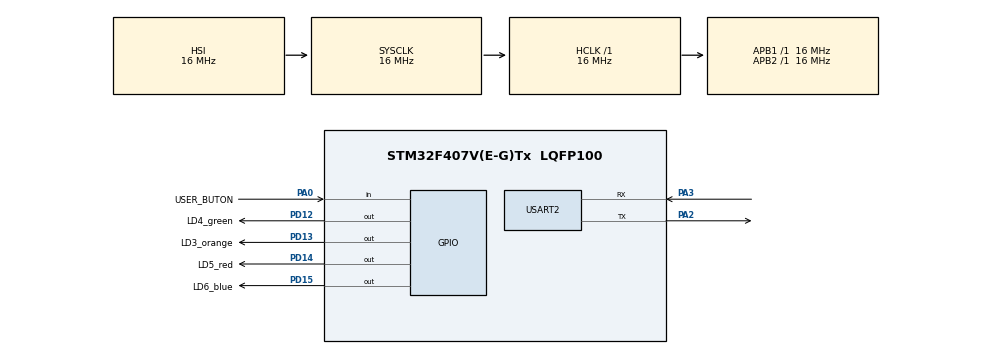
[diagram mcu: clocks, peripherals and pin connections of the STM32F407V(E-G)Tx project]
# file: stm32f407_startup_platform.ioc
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Mcu.Family=STM32F4
Mcu.Name=STM32F407V(E-G)Tx
Mcu.Package=LQFP100
NVIC.PriorityGroup=NVIC_PRIORITYGROUP_4
PA0-WKUP.GPIO_Label=USER_BUTON
PA0-WKUP.Signal=GPIO_Input
PA13.Mode=Serial_Wire
PA13.Signal=SYS_JTMS-SWDIO
PA14.Mode=Serial_Wire
PA14.Signal=SYS_JTCK-SWCLK
PA2.Mode=Asynchronous
PA2.Signal=USART2_TX
PA3.Mode=Asynchronous
PA3.Signal=USART2_RX
PD12.GPIO_Label=LD4_green
PD12.Signal=GPIO_Output
PD13.GPIO_Label=LD3_orange
PD13.Signal=GPIO_Output
PD14.GPIO_Label=LD5_red
PD14.Signal=GPIO_Output
PD15.GPIO_Label=LD6_blue
PD15.Signal=GPIO_Output
ProjectManager.HeapSize=0x200
ProjectManager.StackSize=0x400
ProjectManager.TargetToolchain=STM32CubeIDE
RCC.AHBFreq_Value=16000000
RCC.APB1Freq_Value=16000000
RCC.APB2Freq_Value=16000000
RCC.CortexFreq_Value=16000000
RCC.HSE_VALUE=25000000
RCC.HSI_VALUE=16000000
RCC.LSE_VALUE=32768
RCC.SYSCLKFreq_VALUE=16000000
RCC.VCOOutputFreq_Value=192000000
USART2.VirtualMode=VM_ASYNC
board=custom

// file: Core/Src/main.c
/* USER CODE BEGIN Header */
/**
  ******************************************************************************
  * @file           : main.c
  * @brief          : Main program body
  ******************************************************************************
  * @attention
  *
  * Copyright (c) 2026 STMicroelectronics.
  * All rights reserved.
  *
  * This software is licensed under terms that can be found in the LICENSE file
  * in the root directory of this software component.
  * If no LICENSE file comes with this software, it is provided AS-IS.
  *
  ******************************************************************************
  */
/* USER CODE END Header */
#include "main.h"
#include "usart.h"
#include "gpio.h"

/* USER CODE BEGIN Includes */

#include <string.h>
#include <stdio.h>

/* USER CODE END Includes */

void SystemClock_Config(void);

int main(void)
{

  /* MCU Configuration--------------------------------------------------------*/

  /* Reset of all peripherals, Initializes the Flash interface and the Systick. */
  HAL_Init();

  /* Configure the system clock */
  SystemClock_Config();

  /* Initialize all configured peripherals */
  MX_GPIO_Init();
  MX_USART2_UART_Init();
  /* USER CODE BEGIN 2 */

  char header[] = "timestamp_ms,button_state,status\r\n";
  HAL_UART_Transmit(&huart2, (uint8_t*)header, strlen(header), HAL_MAX_DELAY);

  /* USER CODE END 2 */

  /* Infinite loop */
  /* USER CODE BEGIN WHILE */
  while (1)
  {
	  uint32_t timestamp_ms = HAL_GetTick();

	  GPIO_PinState button = HAL_GPIO_ReadPin(USER_BUTON_GPIO_Port, USER_BUTON_Pin);

	  uint8_t button_state = 0;

	  if (button == GPIO_PIN_SET)
	  {
		  button_state = 1;
		  HAL_GPIO_WritePin(LD4_green_GPIO_Port, LD4_green_Pin, GPIO_PIN_SET);
	  }

	  else
	  {
		  button_state = 0;
		  HAL_GPIO_WritePin(LD4_green_GPIO_Port, LD4_green_Pin, GPIO_PIN_RESET);
	  }

	  char tx_buffer[64];

	  int len = snprintf(
	        tx_buffer,
	        sizeof(tx_buffer),
	        "%lu,%d,OK\r\n",
	        (unsigned long)timestamp_ms,
	        button_state
	    );

	  HAL_UART_Transmit(&huart2, (uint8_t*)tx_buffer, len, HAL_MAX_DELAY);

	  HAL_Delay(1000);

	/*char msg[] = "Hello form STM32\r\n";

    HAL_UART_Transmit(&huart2, (uint8_t*)msg, strlen(msg), HAL_MAX_DELAY);

    HAL_GPIO_TogglePin(LD4_green_GPIO_Port, LD4_green_Pin);

    HAL_Delay(1000);*/
  }
  /* USER CODE END 3 */
}

void SystemClock_Config(void)
{
  RCC_OscInitTypeDef RCC_OscInitStruct = {0};
  RCC_ClkInitTypeDef RCC_ClkInitStruct = {0};

  /** Configure the main internal regulator output voltage
  */
  __HAL_RCC_PWR_CLK_ENABLE();
  __HAL_PWR_VOLTAGESCALING_CONFIG(PWR_REGULATOR_VOLTAGE_SCALE1);

  /** Initializes the RCC Oscillators according to the specified parameters
  * in the RCC_OscInitTypeDef structure.
  */
  RCC_OscInitStruct.OscillatorType = RCC_OSCILLATORTYPE_HSI;
  RCC_OscInitStruct.HSIState = RCC_HSI_ON;
  RCC_OscInitStruct.HSICalibrationValue = RCC_HSICALIBRATION_DEFAULT;
  RCC_OscInitStruct.PLL.PLLState = RCC_PLL_NONE;
  if (HAL_RCC_OscConfig(&RCC_OscInitStruct) != HAL_OK)
  {
    Error_Handler();
  }

  /** Initializes the CPU, AHB and APB buses clocks
  */
  RCC_ClkInitStruct.ClockType = RCC_CLOCKTYPE_HCLK|RCC_CLOCKTYPE_SYSCLK
                              |RCC_CLOCKTYPE_PCLK1|RCC_CLOCKTYPE_PCLK2;
  RCC_ClkInitStruct.SYSCLKSource = RCC_SYSCLKSOURCE_HSI;
  RCC_ClkInitStruct.AHBCLKDivider = RCC_SYSCLK_DIV1;
  RCC_ClkInitStruct.APB1CLKDivider = RCC_HCLK_DIV1;
  RCC_ClkInitStruct.APB2CLKDivider = RCC_HCLK_DIV1;

  if (HAL_RCC_ClockConfig(&RCC_ClkInitStruct, FLASH_LATENCY_0) != HAL_OK)
  {
    Error_Handler();
  }
}

void Error_Handler(void)
{
  __disable_irq();
  while (1)
  {
  }
}
